# F28x7x_output_xbar_regs register map
Vendor: Texas Instruments
Peripheral module from a debugger description file (folder C2000).
Address unit: 16 bits
Registers are 32-bit, read-write, no defined reset value unless marked. A register's access mark holds for its fields unless they carry their own. Offsets are as the file gives them; lines under a group give offsets from that group; [hi:lo] are bit positions; {n}, {i} and the like mark numbered series; 'fields as' and 'values as' point back to an identical list; <NAME> marks a mode.

## OUTPUT_XBAR_REGS
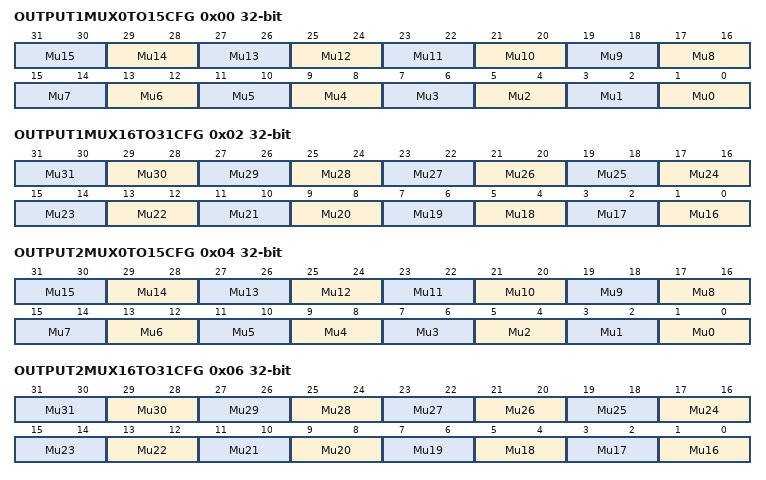
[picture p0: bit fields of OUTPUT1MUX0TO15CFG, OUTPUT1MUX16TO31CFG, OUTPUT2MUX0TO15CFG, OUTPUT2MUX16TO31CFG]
0x00 OUTPUT1MUX0TO15CFG — Output X-BAR Mux Configuration for Output 1
  [2n+1:2n] Mu{n} (n=0..15) — Group Select Bits for Mux{n}: Selects 4X1 group output for OUTPUT1 of OUTPUT-XBAR[[br]][[br]] 00 : Select .1 input for Mux{n}[[br]] 01 : Select .2 input for Mux{n}[[br]] 10 : Select .3 input for Mux{n}[[br]] 11 : Select .4 input for Mux{n}[[br]][[br]]Refer to X-Bar generic architecture diagram for more details
0x02 OUTPUT1MUX16TO31CFG — Output X-BAR Mux Configuration for Output 1
  [2n-31:2n-32] Mu{n} (n=16..31) — Group Select Bits for Mux{n}: Selects 4X1 group output for OUTPUT1 of OUTPUT-XBAR[[br]][[br]] 00 : Select .1 input for Mux{n}[[br]] 01 : Select .2 input for Mux{n}[[br]] 10 : Select .3 input for Mux{n}[[br]] 11 : Select .4 input for Mux{n}[[br]][[br]]Refer to X-Bar generic architecture diagram for more details
0x04 OUTPUT2MUX0TO15CFG — Output X-BAR Mux Configuration for Output 2
  [2n+1:2n] Mu{n} (n=0..15) — Group Select Bits for Mux{n}: Selects 4X1 group output for OUTPUT2 of OUTPUT-XBAR[[br]][[br]] 00 : Select .1 input for Mux{n}[[br]] 01 : Select .2 input for Mux{n}[[br]] 10 : Select .3 input for Mux{n}[[br]] 11 : Select .4 input for Mux{n}[[br]][[br]]Refer to X-Bar generic architecture diagram for more details
0x06 OUTPUT2MUX16TO31CFG — Output X-BAR Mux Configuration for Output 2
  [2n-31:2n-32] Mu{n} (n=16..31) — Group Select Bits for Mux{n}: Selects 4X1 group output for OUTPUT2 of OUTPUT-XBAR[[br]][[br]] 00 : Select .1 input for Mux{n}[[br]] 01 : Select .2 input for Mux{n}[[br]] 10 : Select .3 input for Mux{n}[[br]] 11 : Select .4 input for Mux{n}[[br]][[br]]Refer to X-Bar generic architecture diagram for more details
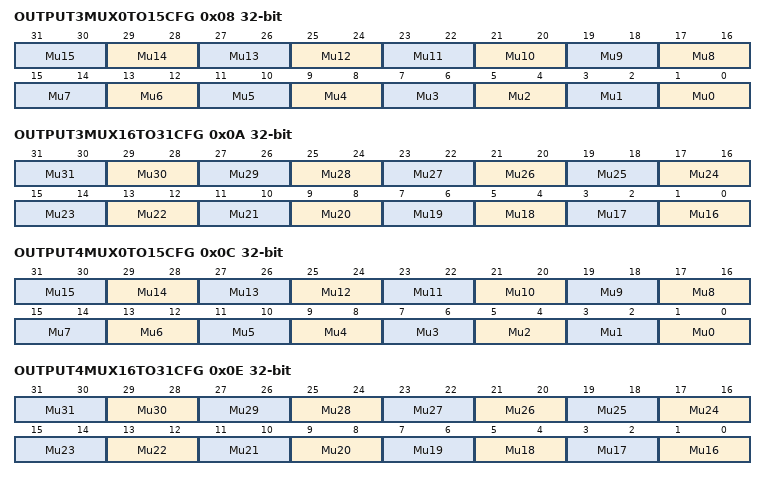
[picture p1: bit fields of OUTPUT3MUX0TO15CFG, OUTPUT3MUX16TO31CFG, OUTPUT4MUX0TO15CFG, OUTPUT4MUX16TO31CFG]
0x08 OUTPUT3MUX0TO15CFG — Output X-BAR Mux Configuration for Output 3
  [2n+1:2n] Mu{n} (n=0..15) — Group Select Bits for Mux{n}: Selects 4X1 group output for OUTPUT3 of OUTPUT-XBAR[[br]][[br]] 00 : Select .1 input for Mux{n}[[br]] 01 : Select .2 input for Mux{n}[[br]] 10 : Select .3 input for Mux{n}[[br]] 11 : Select .4 input for Mux{n}[[br]][[br]]Refer to X-Bar generic architecture diagram for more details
0x0A OUTPUT3MUX16TO31CFG — Output X-BAR Mux Configuration for Output 3
  [2n-31:2n-32] Mu{n} (n=16..31) — Group Select Bits for Mux{n}: Selects 4X1 group output for OUTPUT3 of OUTPUT-XBAR[[br]][[br]] 00 : Select .1 input for Mux{n}[[br]] 01 : Select .2 input for Mux{n}[[br]] 10 : Select .3 input for Mux{n}[[br]] 11 : Select .4 input for Mux{n}[[br]][[br]]Refer to X-Bar generic architecture diagram for more details
0x0C OUTPUT4MUX0TO15CFG — Output X-BAR Mux Configuration for Output 4
  [2n+1:2n] Mu{n} (n=0..15) — Group Select Bits for Mux{n}: Selects 4X1 group output for OUTPUT4 of OUTPUT-XBAR[[br]][[br]] 00 : Select .1 input for Mux{n}[[br]] 01 : Select .2 input for Mux{n}[[br]] 10 : Select .3 input for Mux{n}[[br]] 11 : Select .4 input for Mux{n}[[br]][[br]]Refer to X-Bar generic architecture diagram for more details
0x0E OUTPUT4MUX16TO31CFG — Output X-BAR Mux Configuration for Output 4
  [2n-31:2n-32] Mu{n} (n=16..31) — Group Select Bits for Mux{n}: Selects 4X1 group output for OUTPUT4 of OUTPUT-XBAR[[br]][[br]] 00 : Select .1 input for Mux{n}[[br]] 01 : Select .2 input for Mux{n}[[br]] 10 : Select .3 input for Mux{n}[[br]] 11 : Select .4 input for Mux{n}[[br]][[br]]Refer to X-Bar generic architecture diagram for more details
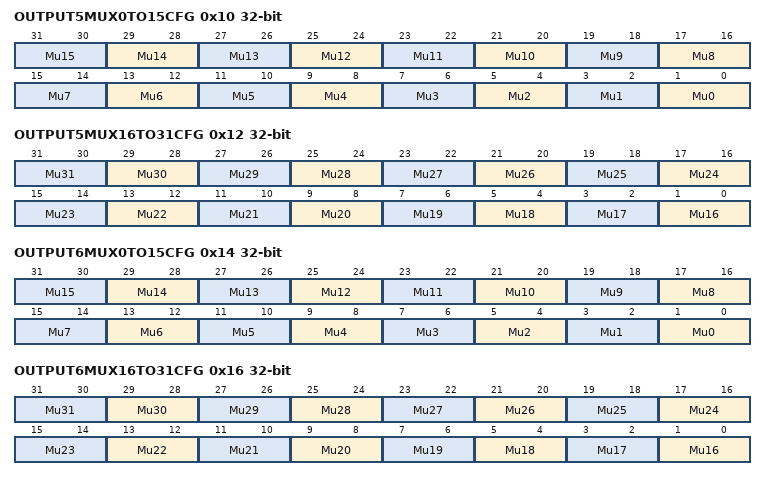
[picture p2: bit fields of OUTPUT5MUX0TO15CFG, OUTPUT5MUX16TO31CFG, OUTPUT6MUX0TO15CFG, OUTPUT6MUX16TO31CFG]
0x10 OUTPUT5MUX0TO15CFG — Output X-BAR Mux Configuration for Output 5
  [2n+1:2n] Mu{n} (n=0..15) — Group Select Bits for Mux{n}: Selects 4X1 group output for OUTPUT5 of OUTPUT-XBAR[[br]][[br]] 00 : Select .1 input for Mux{n}[[br]] 01 : Select .2 input for Mux{n}[[br]] 10 : Select .3 input for Mux{n}[[br]] 11 : Select .4 input for Mux{n}[[br]][[br]]Refer to X-Bar generic architecture diagram for more details
0x12 OUTPUT5MUX16TO31CFG — Output X-BAR Mux Configuration for Output 5
  [2n-31:2n-32] Mu{n} (n=16..31) — Group Select Bits for Mux{n}: Selects 4X1 group output for OUTPUT5 of OUTPUT-XBAR[[br]][[br]] 00 : Select .1 input for Mux{n}[[br]] 01 : Select .2 input for Mux{n}[[br]] 10 : Select .3 input for Mux{n}[[br]] 11 : Select .4 input for Mux{n}[[br]][[br]]Refer to X-Bar generic architecture diagram for more details
0x14 OUTPUT6MUX0TO15CFG — Output X-BAR Mux Configuration for Output 6
  [2n+1:2n] Mu{n} (n=0..15) — Group Select Bits for Mux{n}: Selects 4X1 group output for OUTPUT6 of OUTPUT-XBAR[[br]][[br]] 00 : Select .1 input for Mux{n}[[br]] 01 : Select .2 input for Mux{n}[[br]] 10 : Select .3 input for Mux{n}[[br]] 11 : Select .4 input for Mux{n}[[br]][[br]]Refer to X-Bar generic architecture diagram for more details
0x16 OUTPUT6MUX16TO31CFG — Output X-BAR Mux Configuration for Output 6
  [2n-31:2n-32] Mu{n} (n=16..31) — Group Select Bits for Mux{n}: Selects 4X1 group output for OUTPUT6 of OUTPUT-XBAR[[br]][[br]] 00 : Select .1 input for Mux{n}[[br]] 01 : Select .2 input for Mux{n}[[br]] 10 : Select .3 input for Mux{n}[[br]] 11 : Select .4 input for Mux{n}[[br]][[br]]Refer to X-Bar generic architecture diagram for more details
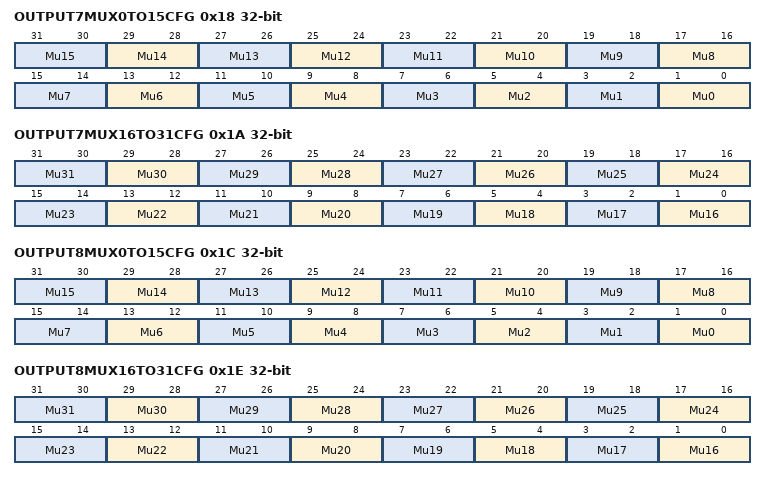
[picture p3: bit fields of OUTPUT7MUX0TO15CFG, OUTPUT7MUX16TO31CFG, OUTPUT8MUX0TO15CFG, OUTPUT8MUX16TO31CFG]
0x18 OUTPUT7MUX0TO15CFG — Output X-BAR Mux Configuration for Output 7
  [2n+1:2n] Mu{n} (n=0..15) — Group Select Bits for Mux{n}: Selects 4X1 group output for OUTPUT7 of OUTPUT-XBAR[[br]][[br]] 00 : Select .1 input for Mux{n}[[br]] 01 : Select .2 input for Mux{n}[[br]] 10 : Select .3 input for Mux{n}[[br]] 11 : Select .4 input for Mux{n}[[br]][[br]]Refer to X-Bar generic architecture diagram for more details
0x1A OUTPUT7MUX16TO31CFG — Output X-BAR Mux Configuration for Output 7
  [2n-31:2n-32] Mu{n} (n=16..31) — Group Select Bits for Mux{n}: Selects 4X1 group output for OUTPUT7 of OUTPUT-XBAR[[br]][[br]] 00 : Select .1 input for Mux{n}[[br]] 01 : Select .2 input for Mux{n}[[br]] 10 : Select .3 input for Mux{n}[[br]] 11 : Select .4 input for Mux{n}[[br]][[br]]Refer to X-Bar generic architecture diagram for more details
0x1C OUTPUT8MUX0TO15CFG — Output X-BAR Mux Configuration for Output 8
  [2n+1:2n] Mu{n} (n=0..15) — Group Select Bits for Mux{n}: Selects 4X1 group output for OUTPUT8 of OUTPUT-XBAR[[br]][[br]] 00 : Select .1 input for Mux{n}[[br]] 01 : Select .2 input for Mux{n}[[br]] 10 : Select .3 input for Mux{n}[[br]] 11 : Select .4 input for Mux{n}[[br]][[br]]Refer to X-Bar generic architecture diagram for more details
0x1E OUTPUT8MUX16TO31CFG — Output X-BAR Mux Configuration for Output 8
  [2n-31:2n-32] Mu{n} (n=16..31) — Group Select Bits for Mux{n}: Selects 4X1 group output for OUTPUT8 of OUTPUT-XBAR[[br]][[br]] 00 : Select .1 input for Mux{n}[[br]] 01 : Select .2 input for Mux{n}[[br]] 10 : Select .3 input for Mux{n}[[br]] 11 : Select .4 input for Mux{n}[[br]][[br]]Refer to X-Bar generic architecture diagram for more details
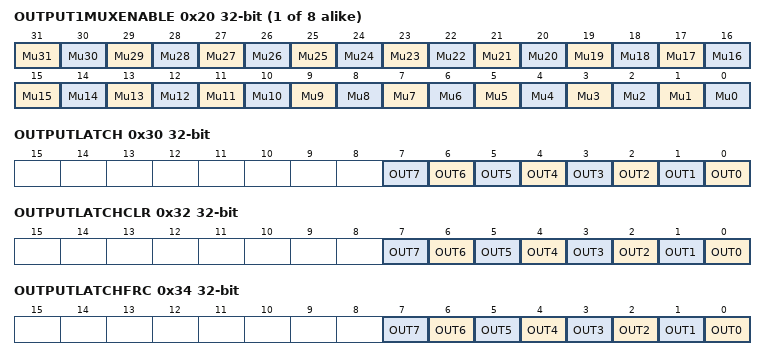
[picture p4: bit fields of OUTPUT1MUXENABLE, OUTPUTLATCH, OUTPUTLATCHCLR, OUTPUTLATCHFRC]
{0x1E+2i} OUTPUT{i}MUXENABLE (i=1..8) — Output X-BAR Mux Enable for Output {i}
  [n] Mu{n} (n=1..31) — Selects the output of Mux{n} to drive OUTPUT{i} of OUTPUT-XBAR[[br]][[br]] 0: Respective output of Mux{n} is enabled to drive the OUTPUT{i} of OUTPUT-XBAR[[br]] 1: Respective output of Mux{n} is disabled to drive the OUTPUT{i} of OUTPUT-XBAR[[br]][[br]]Refer to X-Bar generic architecture diagram for more details
  [0] Mu0 — Selects the output of mux0 to drive OUTPUT{i} of OUTPUT-XBAR[[br]][[br]] 0: Respective output of Mux0 is enabled to drive the OUTPUT{i} of OUTPUT-XBAR[[br]] 1: Respective output of Mux0 is disabled to drive the OUTPUT{i} of OUTPUT-XBAR[[br]][[br]]Refer to X-Bar generic architecture diagram for more details
0x30 OUTPUTLATCH — Output X-BAR Output Latch
  [n] OUT{n} (n=0..7) — Records the OUTPUT{n+1} of OUTPUT-XBAR
0x32 OUTPUTLATCHCLR — Output X-BAR Output Latch Clear
  [n] OUT{n} (n=0..7) — Clears the Output-Latch for OUTPUT{n+1} of OUTPUT-XBAR
0x34 OUTPUTLATCHFRC — Output X-BAR Output Latch Clear
  [n] OUT{n} (n=0..7) — Sets the Output-Latch for OUTPUT{n+1} of OUTPUT-XBAR
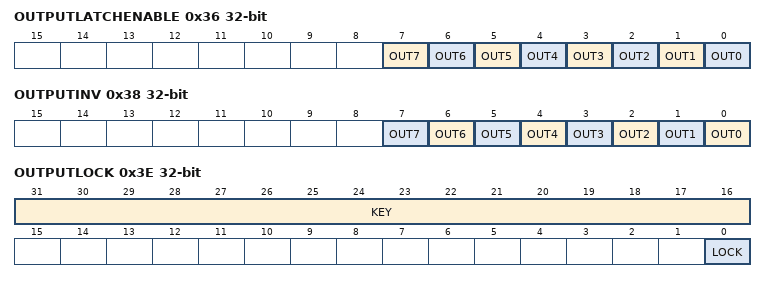
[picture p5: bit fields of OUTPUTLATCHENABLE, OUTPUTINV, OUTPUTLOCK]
0x36 OUTPUTLATCHENABLE — Output X-BAR Output Latch Enable
  [n] OUT{n} (n=1..7) — Selects the output latch to drive output{n} for OUTPUT-XBAR
  [0] OUT0 — Selects the output latch to drive OUTPUT1 for OUTPUT-XBAR
0x38 OUTPUTINV — Output X-BAR Output Inversion
  [n] OUT{n} (n=0..7) — Selects polarity for OUTPUT{n+1} of OUTPUT-XBAR
0x3E OUTPUTLOCK — Output X-BAR Configuration Lock register
  [31:16] KEY — Write Protection KEY
  [0] LOCK — Locks the configuration for OUTPUT-XBAR
